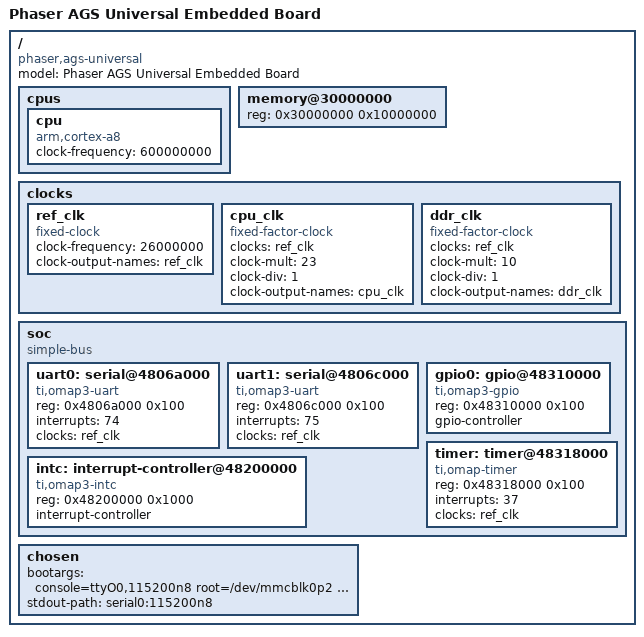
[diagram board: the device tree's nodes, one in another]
/dts-v1/;

/ {
	model = "Phaser AGS Universal Embedded Board";
	compatible = "phaser,ags-universal";
	#address-cells = <1>;
	#size-cells = <1>;

	cpus {
		#address-cells = <0>;
		#size-cells = <0>;
		cpu {
			device_type = "cpu";
			compatible = "arm,cortex-a8";
			clock-frequency = <600000000>;
		};
	};

	memory@30000000 {
		device_type = "memory";
		reg = <0x30000000 0x10000000>;
	};

	clocks {
		#address-cells = <1>;
		#size-cells = <0>;

		ref_clk: ref_clk {
			compatible = "fixed-clock";
			#clock-cells = <0>;
			clock-frequency = <26000000>;
			clock-output-names = "ref_clk";
		};

		cpu_clk: cpu_clk {
			compatible = "fixed-factor-clock";
			clocks = <&ref_clk>;
			clock-mult = <23>;
			clock-div = <1>;
			clock-output-names = "cpu_clk";
		};

		ddr_clk: ddr_clk {
			compatible = "fixed-factor-clock";
			clocks = <&ref_clk>;
			clock-mult = <10>;
			clock-div = <1>;
			clock-output-names = "ddr_clk";
		};
	};

	soc {
		#address-cells = <1>;
		#size-cells = <1>;
		compatible = "simple-bus";
		ranges;

		uart0: serial@4806a000 {
			compatible = "ti,omap3-uart";
			reg = <0x4806a000 0x100>;
			interrupts = <74>;
			clocks = <&ref_clk>;
			status = "okay";
		};

		uart1: serial@4806c000 {
			compatible = "ti,omap3-uart";
			reg = <0x4806c000 0x100>;
			interrupts = <75>;
			clocks = <&ref_clk>;
			status = "okay";
		};

		gpio0: gpio@48310000 {
			compatible = "ti,omap3-gpio";
			reg = <0x48310000 0x100>;
			#gpio-cells = <2>;
			gpio-controller;
		};

		intc: interrupt-controller@48200000 {
			compatible = "ti,omap3-intc";
			reg = <0x48200000 0x1000>;
			#interrupt-cells = <1>;
			interrupt-controller;
		};

		timer: timer@48318000 {
			compatible = "ti,omap-timer";
			reg = <0x48318000 0x100>;
			interrupts = <37>;
			clocks = <&ref_clk>;
		};
	};

	chosen {
		bootargs = "console=ttyO0,115200n8 root=/dev/mmcblk0p2 rw rootwait";
		stdout-path = "serial0:115200n8";
	};
};
